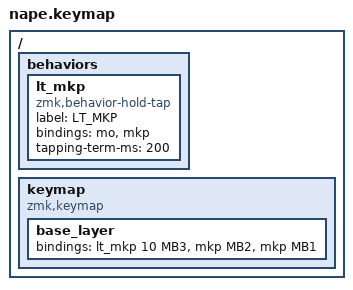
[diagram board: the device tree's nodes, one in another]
#include <dt-bindings/zmk/mouse.h>
#include <dt-bindings/zmk/keys.h>
#include <dt-bindings/zmk/pointing.h>
#include <behaviors.dtsi>

#define SCROLL 10

/ {
    behaviors {
        lt_mkp: lt_mkp {
            compatible = "zmk,behavior-hold-tap";
            label = "LT_MKP";
            bindings = <&mo>, <&mkp>;
            #binding-cells = <2>;
            tapping-term-ms = <200>;
        };
    };

    keymap {
        compatible = "zmk,keymap";

        base_layer {
            bindings = <
                &lt_mkp 10 MB3   &mkp MB2   &mkp MB1
            >;
        };
    };
};
